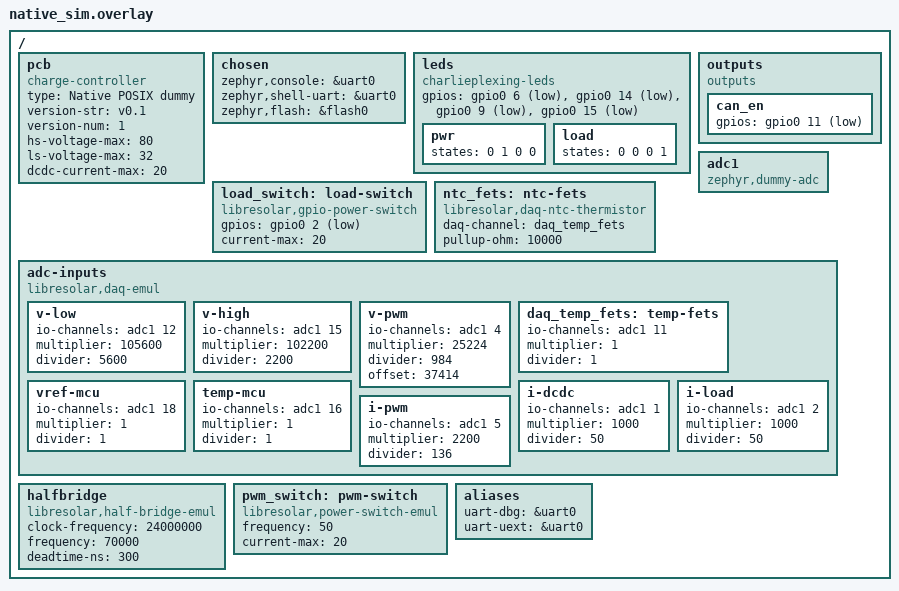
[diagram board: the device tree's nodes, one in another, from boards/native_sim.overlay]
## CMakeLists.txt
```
# Copyright (c) The Libre Solar Project Contributors
# SPDX-License-Identifier: Apache-2.0

set(BOARD_ROOT ${CMAKE_SOURCE_DIR}/../..)
set(DTS_ROOT ${CMAKE_SOURCE_DIR}/../..)

#set(BOARD "native_posix")
#set(ZEPHYR_TOOLCHAIN_VARIANT "host")

cmake_minimum_required(VERSION 3.13.1)
find_package(Zephyr REQUIRED HINTS $ENV{ZEPHYR_BASE})

project(libre_solar_charge_controller)
add_definitions(-DUNIT_TEST=1)

add_subdirectory(../../app/src build/app)

zephyr_include_directories(./src)
zephyr_include_directories(../../app/src)

zephyr_include_directories(../../../modules/thingset/src)

target_sources(app PRIVATE
        src/daq_stub.cpp
        src/tests_bat_charger.cpp
        src/tests_daq.cpp
        src/tests_dcdc.cpp
        src/tests_device_status.cpp
        src/tests_load.cpp
        src/tests_power_port.cpp
)

# determine git tag and commit hash for automatic firmware versioning
find_package(Git)
if(GIT_FOUND)
    execute_process(
        COMMAND ${GIT_EXECUTABLE} describe --long --dirty --tags
        OUTPUT_VARIABLE FIRMWARE_VERSION_ID
        OUTPUT_STRIP_TRAILING_WHITESPACE)
else()
    set(FIRMWARE_VERSION_ID "unknown")
endif()
add_definitions(-DFIRMWARE_VERSION_ID="${FIRMWARE_VERSION_ID}")
```

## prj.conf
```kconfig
# Main application configuration (overrides board-specific settings)

CONFIG_ZTEST=y

# only very small heap necessary for malloc in printf statements with %f
CONFIG_HEAP_MEM_POOL_SIZE=256

CONFIG_CPP=y
CONFIG_REQUIRES_FULL_LIBCPP=y

#CONFIG_WATCHDOG=y
CONFIG_TASK_WDT=y
CONFIG_THREAD_NAME=y

CONFIG_REBOOT=y

CONFIG_HWINFO=y

CONFIG_SENSOR=y

CONFIG_CONSOLE_SUBSYS=y

CONFIG_LOG=y
CONFIG_LOG_MODE_MINIMAL=y
CONFIG_CBPRINTF_FP_SUPPORT=y

# RNG required for ThingSet node ID generation in native_posix
CONFIG_ENTROPY_GENERATOR=y

CONFIG_THINGSET=y
CONFIG_THINGSET_SDK=y

# ThingSet protocol interface via UART serial
CONFIG_THINGSET_SERIAL=n

# Disable regular data publication on ThingSet serial at startup
CONFIG_THINGSET_REPORTING_LIVE_ENABLE_PRESET=n
```

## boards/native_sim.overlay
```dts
/*
 * Copyright (c) The Libre Solar Project Contributors
 *
 * SPDX-License-Identifier: Apache-2.0
 */

/ {
	/* delete conflicting nodes from Zephyr native_sim board */
	/delete-node/ leds;
	/delete-node/ aliases;

	pcb {
		compatible = "charge-controller";

		type = "Native POSIX dummy";
		version-str = "v0.1";
		version-num = <1>;

		hs-voltage-max = <80>;
		ls-voltage-max = <32>;
		dcdc-current-max = <20>;
	};

	chosen {
		zephyr,console = &uart0;
		zephyr,shell-uart = &uart0;
		zephyr,flash = &flash0;
	};

	leds {
		compatible = "charlieplexing-leds";
		gpios = <&gpio0 6 GPIO_ACTIVE_LOW>,	/* chg red */
			<&gpio0 14 GPIO_ACTIVE_LOW>,	/* chg green */
			<&gpio0 9 GPIO_ACTIVE_LOW>,	/* dis red */
			<&gpio0 15 GPIO_ACTIVE_LOW>;	/* dis green */

		pwr {
			states = <0 1 0 0>;
		};

		load {
			states = <0 0 0 1>;
		};
	};

	load_switch: load-switch {
		compatible = "libresolar,gpio-power-switch";
		gpios = <&gpio0 2 GPIO_ACTIVE_LOW>;
		current-max = <20>;
	};

	outputs {
		compatible = "outputs";

		can_en {
			gpios = <&gpio0 11 GPIO_ACTIVE_LOW>;
		};
	};

        adc1: adc1 {
		compatible = "zephyr,dummy-adc";
		#io-channel-cells = <1>;
        };

	ntc_fets: ntc-fets {
		compatible = "libresolar,daq-ntc-thermistor";
		daq-channel = <&daq_temp_fets>;
		pullup-ohm = <10000>;
	};

	adc-inputs {
		compatible = "libresolar,daq-emul";

		v-low {
			io-channels = <&adc1 12>;
			multiplier = <105600>;
			divider = <5600>;
		};

		v-high {
			io-channels = <&adc1 15>;
			multiplier = <102200>;
			divider = <2200>;
		};

		v-pwm {
			io-channels = <&adc1 4>;
			multiplier = <25224>;	// (12*8.2 + 120*8.2 + 120*12) * 10
			divider = <984>;	// (8.2*12) * 10
			offset = <37414>;	// 65536 / (1 + 8.2/120 + 8.2/12)
		};

		daq_temp_fets: temp-fets {
			io-channels = <&adc1 11>;
			multiplier = <1>;
			divider = <1>;
		};

		vref-mcu {
			io-channels = <&adc1 18>;
			multiplier = <1>;
			divider = <1>;
		};

		temp-mcu {
			io-channels = <&adc1 16>;
			multiplier = <1>;
			divider = <1>;
		};

		i-dcdc {
			io-channels = <&adc1 1>;
			// amp gain: 25, resistor: 2 mOhm
			multiplier = <1000>;	// 1000
			divider = <50>;	// 2*25
		};

		i-load {
			io-channels = <&adc1 2>;
			// amp gain: 25, resistor: 2 mOhm
			multiplier = <1000>;	// 1000
			divider = <50>;	// 2*25
		};

		i-pwm {
			io-channels = <&adc1 5>;
			// amp gain: 68/2.2, resistor: 2 mOhm
			multiplier = <2200>;	// 1000*2.2
			divider = <136>;	// 2*68
		};
	};

	halfbridge: halfbridge {
		compatible = "libresolar,half-bridge-emul";
		clock-frequency = <24000000>;
		frequency = <70000>;
		deadtime-ns = <300>;
	};

	pwm_switch: pwm-switch {
		compatible = "libresolar,power-switch-emul";
		frequency = <50>;
		current-max = <20>;
	};

	aliases {
		uart-dbg = &uart0;
		uart-uext = &uart0;
//		spi-uext = &spi1;
//		i2c-uext = &i2c1;
	};
};
```

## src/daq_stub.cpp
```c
/*
 * Copyright (c) The Libre Solar Project Contributors
 *
 * SPDX-License-Identifier: Apache-2.0
 */

#include "daq_stub.h"

#include <libresolar/drivers/daq_emul.h>

#include "daq.h"

void prepare_adc_readings(AdcValues values)
{
    daq_emul_set_value(DAQ_DEV, DAQ_CH(v_high), values.solar_voltage);
    daq_emul_set_value(DAQ_DEV, DAQ_CH(v_low), values.battery_voltage);
    daq_emul_set_value(DAQ_DEV, DAQ_CH(i_dcdc), values.dcdc_current);
    daq_emul_set_value(DAQ_DEV, DAQ_CH(i_load), values.load_current);
}

void prepare_adc_filtered()
{
    daq_emul_preset_filtered(DAQ_DEV);
}
```

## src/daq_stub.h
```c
/*
 * Copyright (c) The Libre Solar Project Contributors
 *
 * SPDX-License-Identifier: Apache-2.0
 */

#ifndef DAQ_STUB_H_
#define DAQ_STUB_H_

/** Data to fill readings of the emulated DAQ during unit-tests
 */
typedef struct
{
    float solar_voltage;
    float battery_voltage;
    float dcdc_current;
    float load_current;
    float bat_temperature;
    float internal_temperature;
} AdcValues;

/** Set the readings of the emulated DAQ for the next samples */
void prepare_adc_readings(AdcValues values);

/** Set the filtered values of the emulated DAQ to the current readings */
void prepare_adc_filtered();

#endif
```

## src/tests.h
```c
/*
 * Copyright (c) The Libre Solar Project Contributors
 *
 * SPDX-License-Identifier: Apache-2.0
 */

#ifndef TESTS_H_
#define TESTS_H_

#include <zephyr/ztest.h>

#include <math.h>
#include <time.h>

/**
 * Assert that two floating point values are equal within a relative precision of 1e-5
 *
 * Same behavior as TEST_ASSERT_EQUAL_FLOAT of the previously used Unity framework.
 */
#define assert_float_equal(actual, expected) \
    zassert_within((double)(actual), (double)(expected), fabs((double)(expected)) * 1e-5, \
                   #actual " not equal to " #expected)

#endif /* TESTS_H_ */
```

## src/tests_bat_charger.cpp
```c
/*
 * Copyright (c) The Libre Solar Project Contributors
 *
 * SPDX-License-Identifier: Apache-2.0
 */

#include "tests.h"

#include <stdio.h>
#include <time.h>

#include "setup.h"

static void init_structs()
{
    battery_conf_init(&bat_conf, BAT_TYPE_FLOODED, 6, 100);
    charger.init_terminal(&bat_conf);
    charger.state = CHG_STATE_IDLE;
    charger.bat_temperature = 25;
    bat_terminal.bus->voltage = 14.0;
    bat_terminal.bus->voltage_filtered = 14.0;
    bat_terminal.current = 0;
}

ZTEST(bat_charger, test_no_start_at_high_voltage)
{
    init_structs();
    bat_terminal.bus->voltage = bat_conf.recharge_voltage + 0.1f;
    charger.charge_control(&bat_conf);
    zassert_equal(charger.state, CHG_STATE_IDLE);
}

ZTEST(bat_charger, test_no_start_after_short_rest)
{
    init_structs();
    charger.time_state_changed = time(NULL) - bat_conf.time_limit_recharge + 1;
    bat_terminal.bus->voltage = bat_conf.recharge_voltage - 0.1f;
    charger.charge_control(&bat_conf);
    zassert_equal(charger.state, CHG_STATE_IDLE);
}

ZTEST(bat_charger, test_no_start_outside_temperature_limits)
{
    init_structs();
    charger.bat_temperature = bat_conf.charge_temp_max + 1;
    bat_terminal.bus->voltage = bat_conf.recharge_voltage - 0.1f;
    charger.charge_control(&bat_conf);
    zassert_equal(charger.state, CHG_STATE_IDLE);

    charger.bat_temperature = bat_conf.charge_temp_min - 1;
    charger.charge_control(&bat_conf);
    zassert_equal(charger.state, CHG_STATE_IDLE);
}

ZTEST(bat_charger, test_start_if_everything_just_fine)
{
    init_structs();
    charger.time_state_changed = time(NULL) - bat_conf.time_limit_recharge - 1;
    bat_terminal.bus->voltage = bat_conf.recharge_voltage - 0.1f;
    charger.charge_control(&bat_conf);
    zassert_equal(charger.state, CHG_STATE_BULK);
}

static void enter_topping_at_voltage_setpoint()
{
    init_structs();
    charger.time_state_changed = time(NULL) - bat_conf.time_limit_recharge - 1;
    bat_terminal.bus->voltage = bat_conf.recharge_voltage - 0.1f;
    bat_terminal.bus->voltage_filtered = bat_terminal.bus->voltage;
    charger.charge_control(&bat_conf);
    zassert_equal(charger.state, CHG_STATE_BULK);
    bat_terminal.bus->voltage = bat_conf.topping_voltage + 0.1f;
    bat_terminal.bus->voltage_filtered = bat_terminal.bus->voltage;
    charger.charge_control(&bat_conf);
    zassert_equal(charger.state, CHG_STATE_TOPPING);
}

ZTEST(bat_charger, test_topping_to_bulk_after_8h_low_power)
{
    enter_topping_at_voltage_setpoint();

    charger.time_state_changed = time(NULL) - 8 * 60 * 60 + 1;
    bat_terminal.bus->voltage = bat_conf.topping_voltage - 0.1f;
    bat_terminal.bus->voltage_filtered = bat_terminal.bus->voltage;
    bat_terminal.current = bat_conf.topping_cutoff_current + 0.1f;
    bat_terminal.current_filtered = bat_terminal.current;

    charger.charge_control(&bat_conf);
    zassert_equal(charger.state, CHG_STATE_TOPPING);

    charger.time_state_changed = time(NULL) - 8 * 60 * 60 - 1;
    charger.charge_control(&bat_conf);
    zassert_equal(charger.state, CHG_STATE_BULK);
}

ZTEST(bat_charger, test_stop_topping_after_time_limit)
{
    enter_topping_at_voltage_setpoint();

    charger.target_voltage_timer = bat_conf.topping_duration - 1;
    bat_terminal.current = bat_conf.topping_cutoff_current + 0.1f;
    bat_terminal.current_filtered = bat_terminal.current;
    bat_terminal.bus->voltage =
        bat_conf.topping_voltage - bat_terminal.current * bat_terminal.bus->sink_droop_res + 0.1f;
    bat_terminal.bus->voltage_filtered = bat_terminal.bus->voltage;

    charger.charge_control(&bat_conf);
    zassert_equal(charger.state, CHG_STATE_TOPPING);

    charger.target_voltage_timer = bat_conf.topping_duration + 1;
    charger.charge_control(&bat_conf);
    zassert_equal(charger.state, CHG_STATE_FLOAT);
}

ZTEST(bat_charger, test_stop_topping_at_cutoff_current)
{
    enter_topping_at_voltage_setpoint();

    charger.target_voltage_timer = 0;
    bat_terminal.current = bat_conf.topping_cutoff_current - 0.1f;
    bat_terminal.current_filtered = bat_terminal.current;
    bat_terminal.bus->voltage =
        bat_conf.topping_voltage - bat_terminal.current * bat_terminal.bus->sink_droop_res + 0.1f;
    bat_terminal.bus->voltage_filtered = bat_terminal.bus->voltage;
    charger.charge_control(&bat_conf);
    zassert_equal(charger.state, CHG_STATE_FLOAT);
}

ZTEST(bat_charger, test_float_to_idle_for_li_ion)
{
    enter_topping_at_voltage_setpoint();
    battery_conf_init(&bat_conf, BAT_TYPE_LFP, 4, 100);

    charger.time_state_changed = time(NULL) - 1;
    bat_terminal.current = bat_conf.topping_cutoff_current - 0.1f;
    bat_terminal.bus->voltage =
        bat_conf.topping_voltage - bat_terminal.current * bat_terminal.bus->sink_droop_res + 0.1f;
    charger.charge_control(&bat_conf);
    zassert_equal(charger.state, CHG_STATE_IDLE);
}

ZTEST(bat_charger, test_no_equalization_if_disabled)
{
    enter_topping_at_voltage_setpoint();
    bat_conf.equalization_enabled = false;

    // set triggers such that it would normally start
    charger.deep_dis_last_equalization =
        charger.num_deep_discharges - bat_conf.equalization_trigger_deep_cycles;
    charger.time_last_equalization = time(NULL) - bat_conf.equalization_trigger_days * 24 * 60 * 60;

    charger.time_state_changed = time(NULL) - 1;
    bat_terminal.bus->voltage = bat_conf.topping_voltage + 0.1f;
    bat_terminal.current = bat_conf.topping_cutoff_current - 0.1f;
    charger.charge_control(&bat_conf);
    zassert_not_equal(charger.state, CHG_STATE_EQUALIZATION);
}

ZTEST(bat_charger, test_no_equalization_if_limits_not_reached)
{
    enter_topping_at_voltage_setpoint();
    bat_conf.equalization_enabled = true;

    // set triggers such that they are just NOT reached
    charger.deep_dis_last_equalization =
        charger.num_deep_discharges - bat_conf.equalization_trigger_deep_cycles + 1;
    charger.time_last_equalization =
        time(NULL) - (bat_conf.equalization_trigger_days - 1) * 24 * 60 * 60;

    charger.time_state_changed = time(NULL) - 1;
    bat_terminal.bus->voltage = bat_conf.topping_voltage + 0.1f;
    bat_terminal.current = bat_conf.topping_cutoff_current - 0.1f;
    charger.charge_control(&bat_conf);
    zassert_not_equal(charger.state, CHG_STATE_EQUALIZATION);
}

static void float_to_equalization_if_enabled_and_time_limit_reached()
{
    enter_topping_at_voltage_setpoint();
    bat_conf.equalization_enabled = true;
    charger.time_last_equalization = time(NULL) - bat_conf.equalization_trigger_days * 24 * 60 * 60;

    charger.time_state_changed = time(NULL) - 1;
    bat_terminal.current = bat_conf.topping_cutoff_current - 0.1f;
    bat_terminal.bus->voltage =
        bat_conf.topping_voltage - bat_terminal.current * bat_terminal.bus->sink_droop_res + 0.1f;
    charger.charge_control(&bat_conf);
    zassert_equal(charger.state, CHG_STATE_EQUALIZATION);
}

ZTEST(bat_charger, test_float_to_equalization_if_enabled_and_deep_dis_limit_reached)
{
    enter_topping_at_voltage_setpoint();
    bat_conf.equalization_enabled = true;
    charger.deep_dis_last_equalization =
        charger.num_deep_discharges - bat_conf.equalization_trigger_deep_cycles;

    charger.time_state_changed = time(NULL) - 1;
    bat_terminal.current = bat_conf.topping_cutoff_current - 0.1f;
    bat_terminal.bus->voltage =
        bat_conf.topping_voltage - bat_terminal.current * bat_terminal.bus->sink_droop_res + 0.1f;
    charger.charge_control(&bat_conf);
    zassert_equal(charger.state, CHG_STATE_EQUALIZATION);
}

ZTEST(bat_charger, test_stop_equalization_after_time_limit)
{
    float_to_equalization_if_enabled_and_time_limit_reached();

    charger.time_state_changed = time(NULL) - bat_conf.equalization_duration + 1;
    bat_terminal.bus->voltage = bat_conf.equalization_voltage
                                - bat_terminal.current * bat_terminal.bus->sink_droop_res + 0.1f;

    charger.charge_control(&bat_conf);
    zassert_equal(charger.state, CHG_STATE_EQUALIZATION);

    charger.time_state_changed = time(NULL) - bat_conf.topping_duration - 1;
    charger.charge_control(&bat_conf);
    zassert_equal(charger.state, CHG_STATE_FLOAT);
}

void restart_bulk_from_float_if_voltage_drops()
{
    zassert_true(0);
}

ZTEST(bat_charger, test_stop_discharge_at_low_voltage)
{
    init_structs();

    bat_terminal.bus->voltage = 14;
    charger.discharge_control(&bat_conf);
    zassert_true(bat_terminal.neg_current_limit < 0);

    bat_terminal.bus->voltage = bat_conf.absolute_min_voltage - 0.1f;
    charger.discharge_control(&bat_conf);
    zassert_equal(bat_terminal.neg_current_limit, 0);
}

ZTEST(bat_charger, test_stop_discharge_at_overtemp)
{
    init_structs();
    zassert_true(bat_terminal.neg_current_limit < 0);

    charger.bat_temperature = bat_conf.discharge_temp_max + 1;
    charger.discharge_control(&bat_conf);
    zassert_equal(bat_terminal.neg_current_limit, 0);
}

ZTEST(bat_charger, test_stop_discharge_at_undertemp)
{
    init_structs();
    zassert_true(bat_terminal.neg_current_limit < 0);

    charger.bat_temperature = bat_conf.discharge_temp_min - 1;
    charger.discharge_control(&bat_conf);
    zassert_equal(bat_terminal.neg_current_limit, 0);
}

ZTEST(bat_charger, test_restart_discharge_if_allowed)
{
    init_structs();

    // stop because of undervoltage
    bat_terminal.bus->voltage = bat_conf.absolute_min_voltage - 0.1f;
    charger.discharge_control(&bat_conf);
    zassert_equal(bat_terminal.neg_current_limit, 0);

    // increase voltage slightly above absolute minimum
    bat_terminal.bus->voltage = bat_conf.absolute_min_voltage + 0.05f;
    charger.discharge_control(&bat_conf);
    zassert_equal(bat_terminal.neg_current_limit, 0);

    // increase voltage above hysteresis voltage
    bat_terminal.bus->voltage = bat_conf.absolute_min_voltage + 0.15f;
    charger.discharge_control(&bat_conf);
    zassert_true(bat_terminal.neg_current_limit < 0);
}

void battery_values_propagated_to_lv_bus_int()
{
    zassert_true(0);
}

void no_soc_above_100()
{
    zassert_true(0);
}

void no_soc_below_0()
{
    zassert_true(0);
}

ZTEST(bat_charger, test_enter_topping_at_voltage_setpoint)
{
    enter_topping_at_voltage_setpoint();
}

ZTEST(bat_charger, test_float_to_equalization_if_enabled_and_time_limit_reached)
{
    float_to_equalization_if_enabled_and_time_limit_reached();
}

ZTEST_SUITE(bat_charger, NULL, NULL, NULL, NULL, NULL);
```

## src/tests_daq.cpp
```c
/*
 * Copyright (c) The Libre Solar Project Contributors
 *
 * SPDX-License-Identifier: Apache-2.0
 */

#include <libresolar/drivers/daq_emul.h>

#include "daq.h"
#include "daq_stub.h"
#include "helper.h"
#include "setup.h"
#include "tests.h"

#include <stdint.h>

static AdcValues adcval;

ZTEST(daq, test_check_solar_terminal_readings)
{
    assert_float_equal(round(hv_terminal.bus->voltage * 10) / 10, adcval.solar_voltage);
    assert_float_equal(-round(hv_terminal.current * 10) / 10,
                       adcval.dcdc_current / adcval.solar_voltage * adcval.battery_voltage);
}

ZTEST(daq, test_check_bat_terminal_readings)
{
    assert_float_equal(round(lv_terminal.bus->voltage * 10) / 10, adcval.battery_voltage);
    assert_float_equal(round(lv_terminal.current * 10) / 10,
                       adcval.dcdc_current - adcval.load_current);
}

ZTEST(daq, test_check_load_terminal_readings)
{
    assert_float_equal(round(load.bus->voltage * 10) / 10, adcval.battery_voltage);
    assert_float_equal(round(load.current * 10) / 10, adcval.load_current);
}

void check_temperature_readings()
{
    assert_float_equal(round(charger.bat_temperature * 10) / 10, adcval.bat_temperature);
}

ZTEST(daq, test_adc_alert_lv_undervoltage_triggering)
{
    device_status_clear_error(&dev_stat, ERR_ANY_ERROR);
    battery_conf_init(&bat_conf, BAT_TYPE_LFP, 4, 100);
    daq_set_lv_limits(bat_conf.absolute_max_voltage, bat_conf.absolute_min_voltage);
    prepare_adc_filtered();
    daq_emul_process(DAQ_DEV, DAQ_CH(v_low));

    // undervoltage test
    adcval.battery_voltage = bat_conf.absolute_min_voltage - 0.1f;
    prepare_adc_readings(adcval);
    daq_emul_process(DAQ_DEV, DAQ_CH(v_low));
    zassert_equal(device_status_has_error(&dev_stat, ERR_LOAD_VOLTAGE_DIP), false);
    daq_emul_process(DAQ_DEV, DAQ_CH(v_low));
    load.control();
    zassert_equal(flags_check(&load.error_flags, ERR_LOAD_VOLTAGE_DIP), true);
    zassert_equal(load.state, LOAD_STATE_OFF);

    // reset values
    adcval.battery_voltage = 13;
    prepare_adc_readings(adcval);
    prepare_adc_filtered();
    daq_update();

    charger.discharge_control(&bat_conf);
    zassert_equal(device_status_has_error(&dev_stat, ERR_BAT_UNDERVOLTAGE), false); // ToDo
}

ZTEST(daq, test_adc_alert_lv_overvoltage_triggering)
{
    device_status_clear_error(&dev_stat, ERR_ANY_ERROR);
    battery_conf_init(&bat_conf, BAT_TYPE_LFP, 4, 100);
    daq_set_lv_limits(bat_conf.absolute_max_voltage, bat_conf.absolute_min_voltage);
    prepare_adc_filtered();
    daq_emul_process(DAQ_DEV, DAQ_CH(v_low));

    dcdc.state = DCDC_CONTROL_MPPT;

    // overvoltage test
    adcval.battery_voltage = bat_conf.absolute_max_voltage + 0.1f;
    prepare_adc_readings(adcval);
    daq_emul_process(DAQ_DEV, DAQ_CH(v_low));
    zassert_equal(device_status_has_error(&dev_stat, ERR_BAT_OVERVOLTAGE), false);
    daq_emul_process(DAQ_DEV, DAQ_CH(v_low));
    zassert_equal(device_status_has_error(&dev_stat, ERR_BAT_OVERVOLTAGE), true);
    // zassert_equal(pwm_switch.active(), false);
    zassert_equal(dcdc.state, DCDC_CONTROL_OFF);

    // reset values
    adcval.battery_voltage = 12;
    prepare_adc_readings(adcval);
    prepare_adc_filtered();
    daq_update();

    charger.time_state_changed = time(NULL) - bat_conf.time_limit_recharge - 1;
    charger.charge_control(&bat_conf);
    zassert_equal(device_status_has_error(&dev_stat, ERR_BAT_OVERVOLTAGE), false);
}

ZTEST(daq, test_adc_alert_hv_overvoltage_triggering)
{
    device_status_clear_error(&dev_stat, ERR_ANY_ERROR);
    daq_set_hv_limit(DT_PROP(DT_PATH(pcb), hs_voltage_max));
    prepare_adc_filtered();
    daq_emul_process(DAQ_DEV, DAQ_CH(v_high));

    // overvoltage test
    adcval.solar_voltage = 85.0F;
    prepare_adc_readings(adcval);
    daq_emul_process(DAQ_DEV, DAQ_CH(v_high));
    zassert_equal(device_status_has_error(&dev_stat, ERR_DCDC_HS_OVERVOLTAGE), false);
    daq_emul_process(DAQ_DEV, DAQ_CH(v_high));
    zassert_equal(device_status_has_error(&dev_stat, ERR_DCDC_HS_OVERVOLTAGE), true);
    zassert_equal(dcdc.state, DCDC_CONTROL_OFF);
}

/** Data acquisition tests
 *
 * Purpose: Check if raw data from 2 voltage and 2 current measurements are converted
 * to calculated voltage/current measurements of different DC buses
 */
static void daq_before(void *fixture)
{
    ARG_UNUSED(fixture);

    adcval.bat_temperature = 25;
    adcval.battery_voltage = 12;
    adcval.dcdc_current = 3;
    adcval.internal_temperature = 25;
    adcval.load_current = 1;
    adcval.solar_voltage = 30;
    prepare_adc_readings(adcval);
    prepare_adc_filtered();

    // call original daq_update function
    daq_update();
}

ZTEST_SUITE(daq, NULL, NULL, daq_before, NULL, NULL);
```

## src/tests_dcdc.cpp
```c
/*
 * Copyright (c) The Libre Solar Project Contributors
 *
 * SPDX-License-Identifier: Apache-2.0
 */

#include "tests.h"

#include <libresolar/drivers/half_bridge.h>

#include <math.h>
#include <stdio.h>
#include <time.h>

#include "setup.h"

static void init_structs_buck(int num_batteries = 1)
{
    half_bridge_stop(dcdc.half_bridge);

    dev_stat.error_flags = 0;
    power_port_init_solar(&hv_terminal);
    hv_terminal.bus->voltage = 20 * num_batteries;
    hv_terminal.bus->src_voltage_intercept = 18 * num_batteries;
    hv_terminal.bus->series_multiplier = 1;
    hv_terminal.current = 0;
    power_port_update_bus_current_margins(&hv_terminal);

    battery_conf_init(&bat_conf, BAT_TYPE_GEL, 6, 100);
    charger.port = &lv_terminal;
    charger.init_terminal(&bat_conf);
    lv_terminal.bus->voltage = 14 * num_batteries;
    lv_terminal.bus->series_multiplier = num_batteries;
    lv_terminal.current = 0;
    power_port_update_bus_current_margins(&lv_terminal);

    dcdc.mode = DCDC_MODE_BUCK;
    dcdc.temp_mosfets = 25;
    dcdc.off_timestamp = 0;
    dcdc.inductor_current = 0;
    dcdc.power = 0;
    dcdc.power_prev = 0;
    dcdc.pwm_direction = 1;
    dcdc.enable = true;
}

static void start_buck()
{
    dev_stat.error_flags = 0;
    init_structs_buck();
    half_bridge_set_duty_limits(dcdc.half_bridge, 12 / dcdc.hs_voltage_max, 0.97);
    half_bridge_set_duty_cycle(dcdc.half_bridge, 0.97);
    dcdc_control(&dcdc);
    dcdc_control(&dcdc);
    dcdc_control(&dcdc); // call multiple times because of startup delay
    zassert_equal(dcdc.state, DCDC_CONTROL_MPPT);
}

static void init_structs_boost(int num_batteries = 1)
{
    half_bridge_stop(dcdc.half_bridge);

    power_port_init_solar(&hv_terminal);
    lv_terminal.bus->voltage = 20;
    lv_terminal.bus->src_voltage_intercept = 18;
    lv_terminal.bus->series_multiplier = 1;
    dcdc.inductor_current = 0;
    dcdc.power = 0;
    power_port_update_bus_current_margins(&lv_terminal);

    int num_cells = (num_batteries == 1) ? 10 : 5;
    battery_conf_init(&bat_conf, BAT_TYPE_NMC, num_cells, 9);
    charger.port = &hv_terminal;
    charger.init_terminal(&bat_conf);
    hv_terminal.bus->voltage = 3.7 * num_cells * num_batteries;
    hv_terminal.bus->series_multiplier = num_batteries;
    hv_terminal.current = 0;
    hv_terminal.power = 0;
    power_port_update_bus_current_margins(&hv_terminal);

    dcdc.mode = DCDC_MODE_BOOST;
    dcdc.temp_mosfets = 25;
    dcdc.off_timestamp = 0;
    dcdc.power_prev = 0;
    dcdc.pwm_direction = 1;
    dcdc.enable = true;
}

static void start_boost()
{
    init_structs_boost();
    half_bridge_set_duty_limits(dcdc.half_bridge, 12 / dcdc.hs_voltage_max, 0.97);
    half_bridge_set_duty_cycle(dcdc.half_bridge, 0.97);
    dcdc_control(&dcdc);
    dcdc_control(&dcdc);
    dcdc_control(&dcdc); // call multiple times because of startup delay
    zassert_equal(dcdc.state, DCDC_CONTROL_MPPT);
}

ZTEST(dcdc, test_start_valid_mppt_buck)
{
    init_structs_buck();
    zassert_equal(dcdc_check_start_conditions(&dcdc), DCDC_MODE_BUCK);
}

ZTEST(dcdc, test_start_valid_mppt_buck_dual_battery)
{
    init_structs_buck(2);
    zassert_equal(dcdc_check_start_conditions(&dcdc), DCDC_MODE_BUCK);
}

ZTEST(dcdc, test_start_valid_mppt_boost)
{
    init_structs_boost();
    zassert_equal(dcdc_check_start_conditions(&dcdc), DCDC_MODE_BOOST);
}

ZTEST(dcdc, test_start_valid_mppt_boost_dual_battery)
{
    init_structs_boost(2);
    zassert_equal(dcdc_check_start_conditions(&dcdc), DCDC_MODE_BOOST);
}

ZTEST(dcdc, test_no_start_before_restart_delay)
{
    init_structs_buck();
    dcdc.off_timestamp = time(NULL) - dcdc.restart_interval + 1;
    zassert_equal(dcdc_check_start_conditions(&dcdc), DCDC_MODE_OFF);
    dcdc.off_timestamp = time(NULL) - dcdc.restart_interval;
    zassert_equal(dcdc_check_start_conditions(&dcdc), DCDC_MODE_BUCK);
}

ZTEST(dcdc, test_no_start_if_dcdc_disabled)
{
    init_structs_buck();
    dcdc.enable = false;
    zassert_equal(dcdc_check_start_conditions(&dcdc), DCDC_MODE_OFF);
}

ZTEST(dcdc, test_no_start_if_dcdc_lv_voltage_low)
{
    init_structs_buck();
    lv_terminal.bus->voltage = dcdc.ls_voltage_min - 0.5f;
    zassert_equal(dcdc_check_start_conditions(&dcdc), DCDC_MODE_OFF);
}

// buck

ZTEST(dcdc, test_no_buck_start_if_bat_voltage_high)
{
    init_structs_buck();
    lv_terminal.bus->voltage = bat_conf.topping_voltage + 0.1f;
    zassert_equal(dcdc_check_start_conditions(&dcdc), DCDC_MODE_OFF);
}

ZTEST(dcdc, test_no_buck_start_if_bat_chg_not_allowed)
{
    init_structs_buck();
    lv_terminal.bus->sink_current_margin = 0;
    zassert_equal(dcdc_check_start_conditions(&dcdc), DCDC_MODE_OFF);
}

ZTEST(dcdc, test_no_buck_start_if_solar_voltage_high)
{
    init_structs_buck();
    hv_terminal.bus->voltage = dcdc.hs_voltage_max + 1;
    zassert_equal(dcdc_check_start_conditions(&dcdc), DCDC_MODE_OFF);
}

ZTEST(dcdc, test_no_buck_start_if_solar_voltage_low)
{
    init_structs_buck();
    hv_terminal.bus->voltage = 17;
    zassert_equal(dcdc_check_start_conditions(&dcdc), DCDC_MODE_OFF);
}

// boost

ZTEST(dcdc, test_no_boost_start_if_bat_voltage_high)
{
    init_structs_boost();
    hv_terminal.bus->voltage = bat_conf.topping_voltage + 0.1f;
    zassert_equal(dcdc_check_start_conditions(&dcdc), DCDC_MODE_OFF);
}

ZTEST(dcdc, test_no_boost_start_if_bat_chg_not_allowed)
{
    init_structs_boost();
    hv_terminal.bus->sink_current_margin = 0;
    zassert_equal(dcdc_check_start_conditions(&dcdc), DCDC_MODE_OFF);
}

ZTEST(dcdc, test_no_boost_start_if_solar_voltage_high)
{
    init_structs_boost();
    lv_terminal.bus->voltage = dcdc.ls_voltage_max + 1;
    zassert_equal(dcdc_check_start_conditions(&dcdc), DCDC_MODE_OFF);
}

ZTEST(dcdc, test_no_boost_start_if_solar_voltage_low)
{
    init_structs_boost();
    lv_terminal.bus->voltage = 17;
    zassert_equal(dcdc_check_start_conditions(&dcdc), DCDC_MODE_OFF);
}

// buck operation

ZTEST(dcdc, test_buck_increasing_power)
{
    start_buck();
    float pwm_before = half_bridge_get_duty_cycle(dcdc.half_bridge);
    dcdc_control(&dcdc);
    float pwm_after = half_bridge_get_duty_cycle(dcdc.half_bridge);
    zassert_true(pwm_after > pwm_before);
}

ZTEST(dcdc, test_buck_derating_output_voltage_too_high)
{
    start_buck();
    float pwm_before = half_bridge_get_duty_cycle(dcdc.half_bridge);
    lv_terminal.bus->voltage = lv_terminal.bus->sink_voltage_intercept + 0.1f;
    dcdc_control(&dcdc);
    float pwm_after = half_bridge_get_duty_cycle(dcdc.half_bridge);
    zassert_true(pwm_after < pwm_before); // less duty cycle = higher voltage
    zassert_equal(dcdc.state, DCDC_CONTROL_CV_LS);
}

ZTEST(dcdc, test_buck_derating_output_current_too_high)
{
    start_buck();
    float pwm_before = half_bridge_get_duty_cycle(dcdc.half_bridge);
    lv_terminal.current = lv_terminal.pos_current_limit + 0.1f;
    power_port_update_bus_current_margins(&lv_terminal);
    dcdc_control(&dcdc);
    float pwm_after = half_bridge_get_duty_cycle(dcdc.half_bridge);
    zassert_true(pwm_after < pwm_before);
    zassert_equal(dcdc.state, DCDC_CONTROL_CC_LS);
}

ZTEST(dcdc, test_buck_derating_inductor_current_too_high)
{
    start_buck();
    float pwm_before = half_bridge_get_duty_cycle(dcdc.half_bridge);
    dcdc.inductor_current = dcdc.inductor_current_max + 0.1f;
    dcdc_control(&dcdc);
    float pwm_after = half_bridge_get_duty_cycle(dcdc.half_bridge);
    zassert_true(pwm_after < pwm_before);
    zassert_equal(dcdc.state, DCDC_CONTROL_CC_LS);
}

ZTEST(dcdc, test_buck_derating_input_voltage_too_low)
{
    start_buck();
    float pwm_before = half_bridge_get_duty_cycle(dcdc.half_bridge);
    hv_terminal.bus->voltage = hv_terminal.bus->src_voltage_intercept - 0.1f;
    dcdc.power = 1.2f;
    dcdc_control(&dcdc);
    float pwm_after = half_bridge_get_duty_cycle(dcdc.half_bridge);
    zassert_true(pwm_after < pwm_before);
    zassert_equal(dcdc.state, DCDC_CONTROL_CV_HS);
}

ZTEST(dcdc, test_buck_derating_input_current_too_high)
{
    start_buck();
    float pwm_before = half_bridge_get_duty_cycle(dcdc.half_bridge);
    hv_terminal.current = hv_terminal.neg_current_limit - 0.1f;
    power_port_update_bus_current_margins(&hv_terminal);
    dcdc_control(&dcdc);
    float pwm_after = half_bridge_get_duty_cycle(dcdc.half_bridge);
    zassert_true(pwm_after < pwm_before);
    zassert_equal(dcdc.state, DCDC_CONTROL_CC_HS);
}

ZTEST(dcdc, test_buck_derating_temperature_limits_exceeded)
{
    start_buck();
    float pwm_before = half_bridge_get_duty_cycle(dcdc.half_bridge);
    dcdc.temp_mosfets = 81;
    dcdc_control(&dcdc);
    float pwm_after = half_bridge_get_duty_cycle(dcdc.half_bridge);
    zassert_true(pwm_after < pwm_before);
}

ZTEST(dcdc, test_buck_stop_input_power_too_low)
{
    start_buck();
    dcdc.power_good_timestamp = time(NULL) - 11;
    dcdc_control(&dcdc);
    zassert_true(half_bridge_is_enabled(dcdc.half_bridge) == false);
}

ZTEST(dcdc, test_buck_stop_high_voltage_emergency)
{
    start_buck();
    lv_terminal.bus->voltage = dcdc.ls_voltage_max + 0.1f;
    dcdc_control(&dcdc);
    zassert_true(half_bridge_is_enabled(dcdc.half_bridge) == false);
}

ZTEST(dcdc, test_buck_correct_mppt_operation)
{
    start_buck();

    dcdc.power = 5;
    dcdc_control(&dcdc);
    float pwm1 = half_bridge_get_duty_cycle(dcdc.half_bridge);
    dcdc.power = 7;
    dcdc_control(&dcdc);
    float pwm2 = half_bridge_get_duty_cycle(dcdc.half_bridge);
    zassert_true(pwm2 > pwm1);

    dcdc.power = 6; // decrease power to make the direction turn around
    dcdc_control(&dcdc);
    float pwm3 = half_bridge_get_duty_cycle(dcdc.half_bridge);
    zassert_true(pwm3 < pwm2);
}

// boost operation

ZTEST(dcdc, test_boost_increasing_power)
{
    // make sure that without changing anything, dcdc_control goes in direction of increasing power
    start_boost();
    float pwm_before = half_bridge_get_duty_cycle(dcdc.half_bridge);
    dcdc_control(&dcdc);
    float pwm_after = half_bridge_get_duty_cycle(dcdc.half_bridge);
    zassert_true(pwm_after < pwm_before);
}

ZTEST(dcdc, test_boost_derating_output_voltage_too_high)
{
    start_boost();
    float pwm_before = half_bridge_get_duty_cycle(dcdc.half_bridge);
    hv_terminal.bus->voltage = hv_terminal.bus->sink_voltage_intercept + 0.5f;
    dcdc_control(&dcdc);
    float pwm_after = half_bridge_get_duty_cycle(dcdc.half_bridge);
    zassert_true(pwm_after > pwm_before); // higher duty cycle = less power
}

ZTEST(dcdc, test_boost_derating_output_current_too_high)
{
    start_boost();
    float pwm_before = half_bridge_get_duty_cycle(dcdc.half_bridge);
    hv_terminal.current = hv_terminal.pos_current_limit + 0.1f;
    power_port_update_bus_current_margins(&hv_terminal);
    dcdc_control(&dcdc);
    float pwm_after = half_bridge_get_duty_cycle(dcdc.half_bridge);
    zassert_true(pwm_after > pwm_before);
}

ZTEST(dcdc, test_boost_derating_input_voltage_too_low)
{
    start_boost();
    float pwm_before = half_bridge_get_duty_cycle(dcdc.half_bridge);
    lv_terminal.bus->voltage = lv_terminal.bus->src_voltage_intercept - 0.1f;
    dcdc.power = -1.2f;
    power_port_update_bus_current_margins(&hv_terminal);
    dcdc_control(&dcdc);
    float pwm_after = half_bridge_get_duty_cycle(dcdc.half_bridge);
    zassert_equal(dcdc.state, DCDC_CONTROL_CV_LS);
    zassert_true(pwm_after > pwm_before);
}

ZTEST(dcdc, test_boost_derating_input_current_too_high)
{
    start_boost();
    float pwm_before = half_bridge_get_duty_cycle(dcdc.half_bridge);
    dcdc.inductor_current = lv_terminal.neg_current_limit - 0.1f;
    dcdc_control(&dcdc);
    float pwm_after = half_bridge_get_duty_cycle(dcdc.half_bridge);
    zassert_true(pwm_after > pwm_before);
}

ZTEST(dcdc, test_boost_derating_temperature_limits_exceeded)
{
    start_boost();
    float pwm_before = half_bridge_get_duty_cycle(dcdc.half_bridge);
    dcdc.temp_mosfets = 81;
    dcdc_control(&dcdc);
    float pwm_after = half_bridge_get_duty_cycle(dcdc.half_bridge);
    zassert_true(pwm_after > pwm_before);
}

ZTEST(dcdc, test_boost_stop_input_power_too_low)
{
    start_boost();
    dcdc.power_good_timestamp = time(NULL) - 11;
    dcdc_control(&dcdc);
    zassert_true(half_bridge_is_enabled(dcdc.half_bridge) == false);
}

ZTEST(dcdc, test_boost_stop_high_voltage_emergency)
{
    start_boost();
    hv_terminal.bus->voltage = dcdc.hs_voltage_max + 0.1f;
    dcdc_control(&dcdc);
    zassert_true(half_bridge_is_enabled(dcdc.half_bridge) == false);
}

ZTEST(dcdc, test_boost_correct_mppt_operation)
{
    start_boost();

    dcdc.power = -5;
    dcdc_control(&dcdc);
    float pwm1 = half_bridge_get_duty_cycle(dcdc.half_bridge);
    dcdc.power = -7;
    dcdc_control(&dcdc);
    float pwm2 = half_bridge_get_duty_cycle(dcdc.half_bridge);
    zassert_true(pwm2 < pwm1);

    dcdc.power = -6; // decrease power to make the direction turn around
    dcdc_control(&dcdc);
    float pwm3 = half_bridge_get_duty_cycle(dcdc.half_bridge);
    zassert_true(pwm3 > pwm2);
}

ZTEST(dcdc, test_fuse_destruction_forces_low_side_on)
{
    start_buck();
    device_status_set_error(&dev_stat, ERR_DCDC_HS_MOSFET_SHORT);

    // fuse destruction is delayed by 21 calls (seconds) to be able to send out data
    for (int i = 0; i < 21; i++) {
        dcdc_fuse_destruction(&dcdc);
    }
    zassert_not_equal(half_bridge_get_compare(dcdc.half_bridge), 0);

    dcdc_fuse_destruction(&dcdc);
    zassert_true(half_bridge_is_enabled(dcdc.half_bridge));
    zassert_equal(half_bridge_get_compare(dcdc.half_bridge), 0);

    // control loop must not override the forced low side
    dcdc_control(&dcdc);
    zassert_true(half_bridge_is_enabled(dcdc.half_bridge));
    zassert_equal(half_bridge_get_compare(dcdc.half_bridge), 0);

    // forced state is restored after the half bridge was stopped
    dcdc_stop(&dcdc);
    dcdc_fuse_destruction(&dcdc);
    zassert_true(half_bridge_is_enabled(dcdc.half_bridge));
    zassert_equal(half_bridge_get_compare(dcdc.half_bridge), 0);

    dcdc_stop(&dcdc);
    device_status_clear_error(&dev_stat, ERR_DCDC_HS_MOSFET_SHORT);
}

ZTEST_SUITE(dcdc, NULL, NULL, NULL, NULL, NULL);
```

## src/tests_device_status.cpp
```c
/*
 * Copyright (c) The Libre Solar Project Contributors
 *
 * SPDX-License-Identifier: Apache-2.0
 */

#include "tests.h"

#include <math.h>
#include <stdio.h>
#include <time.h>

#include "setup.h"

ZTEST(device_status, test_reset_counters_at_start_of_day)
{
    solar_terminal.bus->voltage = bat_terminal.bus->voltage - 1;

    dev_stat.day_counter = 0;

    solar_terminal.neg_energy_Wh = 10.0;
    bat_terminal.neg_energy_Wh = 3.0;
    bat_terminal.pos_energy_Wh = 4.0;
    load.pos_energy_Wh = 9.0;

    // 5 hours without sun
    for (int i = 0; i <= 5 * 60 * 60; i++) {
        device_status_update_energy(&dev_stat);
    }

    zassert_equal(dev_stat.solar_in_total_Wh, 10);
    zassert_equal(dev_stat.bat_dis_total_Wh, 3);
    zassert_equal(dev_stat.bat_chg_total_Wh, 4);
    zassert_equal(dev_stat.load_out_total_Wh, 9);

    zassert_equal(solar_terminal.neg_energy_Wh, 10);
    zassert_equal(bat_terminal.neg_energy_Wh, 3);
    zassert_equal(bat_terminal.pos_energy_Wh, 4);
    zassert_equal(load.pos_energy_Wh, 9);

    // solar didn't come back yet
    zassert_equal(dev_stat.day_counter, 0);

    // now solar power comes back
    solar_terminal.bus->voltage = bat_terminal.bus->voltage + 1;
    device_status_update_energy(&dev_stat);

    // day counter should be increased and daily energy counters reset
    zassert_equal(dev_stat.day_counter, 1);
    zassert_equal(solar_terminal.neg_energy_Wh, 0);
    zassert_equal(bat_terminal.neg_energy_Wh, 0);
    zassert_equal(bat_terminal.pos_energy_Wh, 0);
    zassert_equal(load.pos_energy_Wh, 0);
}

ZTEST(device_status, test_dev_stat_new_solar_voltage_max)
{
    solar_terminal.bus->voltage = 40;
    device_status_update_min_max_values(&dev_stat);
    zassert_equal(dev_stat.solar_voltage_max, 40);
}

ZTEST(device_status, test_dev_stat_new_bat_voltage_max)
{
    bat_terminal.bus->voltage = 31;
    device_status_update_min_max_values(&dev_stat);
    zassert_equal(dev_stat.battery_voltage_max, 31);
}

ZTEST(device_status, test_dev_stat_new_dcdc_current_max)
{
    dcdc.inductor_current = 21;
    device_status_update_min_max_values(&dev_stat);
    zassert_equal(dev_stat.dcdc_current_max, 21);
}

ZTEST(device_status, test_dev_stat_new_load_current_max)
{
    load.current = 21;
    device_status_update_min_max_values(&dev_stat);
    zassert_equal(dev_stat.load_current_max, 21);
}

ZTEST(device_status, test_dev_stat_solar_power_max)
{
    solar_terminal.power = -50;
    device_status_update_min_max_values(&dev_stat);
    zassert_equal(dev_stat.solar_power_max_day, 50);
    zassert_equal(dev_stat.solar_power_max_total, 50);
}

ZTEST(device_status, test_dev_stat_load_power_max)
{
    load.power = 50;
    device_status_update_min_max_values(&dev_stat);
    zassert_equal(dev_stat.load_power_max_day, 50);
    zassert_equal(dev_stat.load_power_max_total, 50);
}

ZTEST(device_status, test_dev_stat_new_mosfet_temp_max)
{
    dcdc.temp_mosfets = 80;
    device_status_update_min_max_values(&dev_stat);
    zassert_equal(dev_stat.mosfet_temp_max, 80);
}

ZTEST(device_status, test_dev_stat_new_bat_temp_max)
{
    charger.bat_temperature = 45;
    device_status_update_min_max_values(&dev_stat);
    zassert_equal(dev_stat.bat_temp_max, 45);
}

ZTEST(device_status, test_dev_stat_new_int_temp_max)
{
    dev_stat.int_temp_max = 20;
    dev_stat.internal_temp = 22;
    device_status_update_min_max_values(&dev_stat);
    zassert_equal(dev_stat.int_temp_max, 22);
}

ZTEST_SUITE(device_status, NULL, NULL, NULL, NULL, NULL);
```

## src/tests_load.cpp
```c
/*
 * Copyright (c) The Libre Solar Project Contributors
 *
 * SPDX-License-Identifier: Apache-2.0
 */

#include "daq.h"
#include "daq_stub.h"
#include "tests.h"

#include <math.h>
#include <stdio.h>
#include <time.h>

#include "setup.h"

#include <libresolar/drivers/power_switch.h>

static const struct device *const load_switch = DEVICE_DT_GET(LOAD_SWITCH_NODE);

static void load_init(LoadOutput *l, bool on = false, int num_batteries = 1)
{
    l->overvoltage = 14.6;
    l->current = 0;
    l->pos_current_limit = 10;
    l->bus->series_multiplier = num_batteries;
    l->bus->voltage = 14 * num_batteries;
    l->bus->sink_voltage_intercept = 14.4;
    l->bus->src_voltage_intercept = 12;
    l->bus->sink_current_margin = 10;
    l->bus->src_current_margin = -10;
    l->junction_temperature = 25;
    l->error_flags = 0;
    l->enable = true;

    if (on) {
        power_switch_on(load_switch);
        l->state = LOAD_STATE_ON;

        // check if it stays on
        l->control();
        zassert_equal(l->state, LOAD_STATE_ON);
    }
}

ZTEST(load, test_control_off_to_on_if_everything_fine)
{
    struct dc_bus bus;
    dc_bus_init(&bus);
    LoadOutput load_out(&bus, load_switch);
    load_init(&load_out);
    zassert_false(power_switch_is_on(load_switch));

    load_out.enable = true;
    load_out.control();
    zassert_equal(load_out.error_flags, 0);
    zassert_equal(load_out.state, LOAD_STATE_ON);
    zassert_true(power_switch_is_on(load_switch));
}

ZTEST(load, test_control_off_to_on_if_everything_fine_dual_battery)
{
    struct dc_bus bus;
    dc_bus_init(&bus);
    LoadOutput load_out(&bus, load_switch);
    load_init(&load_out, false, 2);

    load_out.enable = true;
    load_out.control();
    zassert_equal(load_out.error_flags, 0);
    zassert_equal(load_out.state, LOAD_STATE_ON);
}

ZTEST(load, test_control_on_to_off_shedding)
{
    struct dc_bus bus;
    dc_bus_init(&bus);
    LoadOutput load_out(&bus, load_switch);
    load_init(&load_out, true);

    bus.voltage = load_out.disconnect_voltage - 0.1f;
    load_out.control();
    zassert_equal(load_out.error_flags, ERR_LOAD_SHEDDING);
    zassert_equal(load_out.state, LOAD_STATE_OFF);
    zassert_false(power_switch_is_on(load_switch));
}

ZTEST(load, test_control_on_to_off_overvoltage)
{
    struct dc_bus bus;
    dc_bus_init(&bus);
    LoadOutput load_out(&bus, load_switch);
    load_init(&load_out, true);

    bus.voltage = bus.sink_voltage_intercept + 0.6f;

    // increase debounce counter to 1 before limit
    for (int i = 0; i < CONFIG_CONTROL_FREQUENCY; i++) {
        load_out.control();
    }

    zassert_equal(load_out.error_flags, 0);
    zassert_equal(load_out.state, LOAD_STATE_ON);

    load_out.control(); // once more
    zassert_equal(load_out.error_flags, ERR_LOAD_OVERVOLTAGE);
    zassert_equal(load_out.state, LOAD_STATE_OFF);
}

ZTEST(load, test_control_on_to_off_overvoltage_dual_battery)
{
    struct dc_bus bus;
    dc_bus_init(&bus);
    LoadOutput load_out(&bus, load_switch);
    load_init(&load_out, true, 2);

    bus.voltage = (bus.sink_voltage_intercept + 0.6f) * bus.series_multiplier;

    // increase debounce counter to 1 before limit
    for (int i = 0; i < CONFIG_CONTROL_FREQUENCY; i++) {
        load_out.control();
    }

    zassert_equal(load_out.error_flags, 0);
    zassert_equal(load_out.state, LOAD_STATE_ON);

    load_out.control(); // once more
    zassert_equal(load_out.error_flags, ERR_LOAD_OVERVOLTAGE);
    zassert_equal(load_out.state, LOAD_STATE_OFF);
}

ZTEST(load, test_control_on_to_off_overcurrent)
{
    struct dc_bus bus;
    dc_bus_init(&bus);
    LoadOutput load_out(&bus, load_switch);
    load_init(&load_out, true);

    // current slightly below factor 2 so that it is not switched off immediately
    load_out.current = DT_PROP(LOAD_SWITCH_NODE, current_max) * 1.9f;
    load_out.control();
    zassert_equal(load_out.state, LOAD_STATE_ON);

    // almost 2x current = 4x heat generation: Should definitely trigger after waiting one time
    // constant
    int trigger_steps = DT_PROP(DT_PATH(pcb), mosfets_tau_ja) * CONFIG_CONTROL_FREQUENCY;
    for (int i = 0; i <= trigger_steps; i++) {
        load_out.control();
    }
    zassert_equal(load_out.error_flags, ERR_LOAD_OVERCURRENT);
    zassert_equal(load_out.state, LOAD_STATE_OFF);
}

ZTEST(load, test_control_on_to_off_voltage_dip)
{
    struct dc_bus bus;
    dc_bus_init(&bus);
    LoadOutput load_out(&bus, load_switch);
    load_init(&load_out, true);

    load_out.stop(ERR_LOAD_VOLTAGE_DIP);
    load_out.control();
    zassert_equal(load_out.error_flags, ERR_LOAD_VOLTAGE_DIP);
    zassert_equal(load_out.state, LOAD_STATE_OFF);
}

ZTEST(load, test_control_on_to_off_bus_limit)
{
    struct dc_bus bus;
    dc_bus_init(&bus);
    LoadOutput load_out(&bus, load_switch);
    load_init(&load_out, true);

    load_out.bus->src_current_margin = 0;
    load_out.control();
    zassert_equal(load_out.error_flags, ERR_LOAD_BUS_SRC_CURRENT);
    zassert_equal(load_out.state, LOAD_STATE_OFF);
}

ZTEST(load, test_control_on_to_off_if_enable_false)
{
    struct dc_bus bus;
    dc_bus_init(&bus);
    LoadOutput load_out(&bus, load_switch);
    load_init(&load_out, true);

    load_out.enable = false;
    load_out.control();
    zassert_equal(load_out.state, LOAD_STATE_OFF);
    zassert_equal(load_out.error_flags, 0);
}

ZTEST(load, test_control_off_shedding_to_on_after_delay)
{
    struct dc_bus bus;
    dc_bus_init(&bus);
    LoadOutput load_out(&bus, load_switch);
    load_init(&load_out);
    load_out.error_flags = ERR_LOAD_SHEDDING;

    load_out.lvd_timestamp = time(NULL) - load_out.lvd_recovery_delay + 1;
    load_out.control();
    zassert_equal(load_out.error_flags, ERR_LOAD_SHEDDING);
    zassert_equal(load_out.state, LOAD_STATE_OFF);

    load_out.lvd_timestamp = time(NULL) - load_out.lvd_recovery_delay - 1;
    load_out.control();
    zassert_equal(load_out.error_flags, 0);
    zassert_equal(load_out.state, LOAD_STATE_ON);
}

ZTEST(load, test_control_off_overcurrent_to_on_after_delay)
{
    struct dc_bus bus;
    dc_bus_init(&bus);
    LoadOutput load_out(&bus, load_switch);
    load_init(&load_out);
    load_out.error_flags = ERR_LOAD_OVERCURRENT;

    load_out.oc_timestamp = time(NULL) - load_out.oc_recovery_delay + 1;
    load_out.control();
    zassert_equal(load_out.error_flags, ERR_LOAD_OVERCURRENT);
    zassert_equal(load_out.state, LOAD_STATE_OFF);

    load_out.oc_timestamp = time(NULL) - load_out.oc_recovery_delay - 1;
    load_out.control();
    zassert_equal(load_out.error_flags, 0);
    zassert_equal(load_out.state, LOAD_STATE_ON);
}

ZTEST(load, test_control_off_overvoltage_to_on_at_lower_voltage)
{
    struct dc_bus bus;
    dc_bus_init(&bus);
    LoadOutput load_out(&bus, load_switch);
    load_init(&load_out);
    bus.voltage = load_out.overvoltage + 0.1f;
    load_out.error_flags = ERR_LOAD_OVERVOLTAGE;

    load_out.control();
    zassert_equal(load_out.error_flags, ERR_LOAD_OVERVOLTAGE);
    zassert_equal(load_out.state, LOAD_STATE_OFF);

    bus.voltage = load_out.overvoltage - 0.1f; // test hysteresis
    load_out.control();
    zassert_equal(load_out.error_flags, ERR_LOAD_OVERVOLTAGE);
    zassert_equal(load_out.state, LOAD_STATE_OFF);

    bus.voltage = load_out.overvoltage - load_out.ov_hysteresis - 0.1f;
    load_out.control();
    zassert_equal(load_out.error_flags, 0);
    zassert_equal(load_out.state, LOAD_STATE_ON);
}

ZTEST(load, test_control_off_overvoltage_to_on_at_lower_voltage_dual_battery)
{
    struct dc_bus bus;
    dc_bus_init(&bus);
    LoadOutput load_out(&bus, load_switch);
    load_init(&load_out, false, 2);
    bus.voltage = (load_out.overvoltage + 0.1f) * bus.series_multiplier;
    load_out.error_flags = ERR_LOAD_OVERVOLTAGE;

    load_out.control();
    zassert_equal(load_out.error_flags, ERR_LOAD_OVERVOLTAGE);
    zassert_equal(load_out.state, LOAD_STATE_OFF);

    bus.voltage = (load_out.overvoltage - 0.1f) * bus.series_multiplier; // test hysteresis
    load_out.control();
    zassert_equal(load_out.error_flags, ERR_LOAD_OVERVOLTAGE);
    zassert_equal(load_out.state, LOAD_STATE_OFF);

    bus.voltage = (load_out.overvoltage - load_out.ov_hysteresis - 0.1f) * bus.series_multiplier;
    load_out.control();
    zassert_equal(load_out.error_flags, 0);
    zassert_equal(load_out.state, LOAD_STATE_ON);
}

ZTEST(load, test_control_off_short_circuit_flag_reset)
{
    struct dc_bus bus;
    dc_bus_init(&bus);
    LoadOutput load_out(&bus, load_switch);
    load_init(&load_out);
    load_out.error_flags = ERR_LOAD_SHORT_CIRCUIT;

    load_out.control();
    zassert_equal(load_out.error_flags, ERR_LOAD_SHORT_CIRCUIT);
    zassert_equal(load_out.state, LOAD_STATE_OFF);

    load_out.enable = false; // this is like a manual reset
    load_out.control();
    zassert_equal(load_out.error_flags, 0);
    zassert_equal(load_out.state, LOAD_STATE_OFF);

    load_out.enable = true;
    load_out.control();
    zassert_equal(load_out.state, LOAD_STATE_ON);
}

ZTEST_SUITE(load, NULL, NULL, NULL, NULL, NULL);
```
